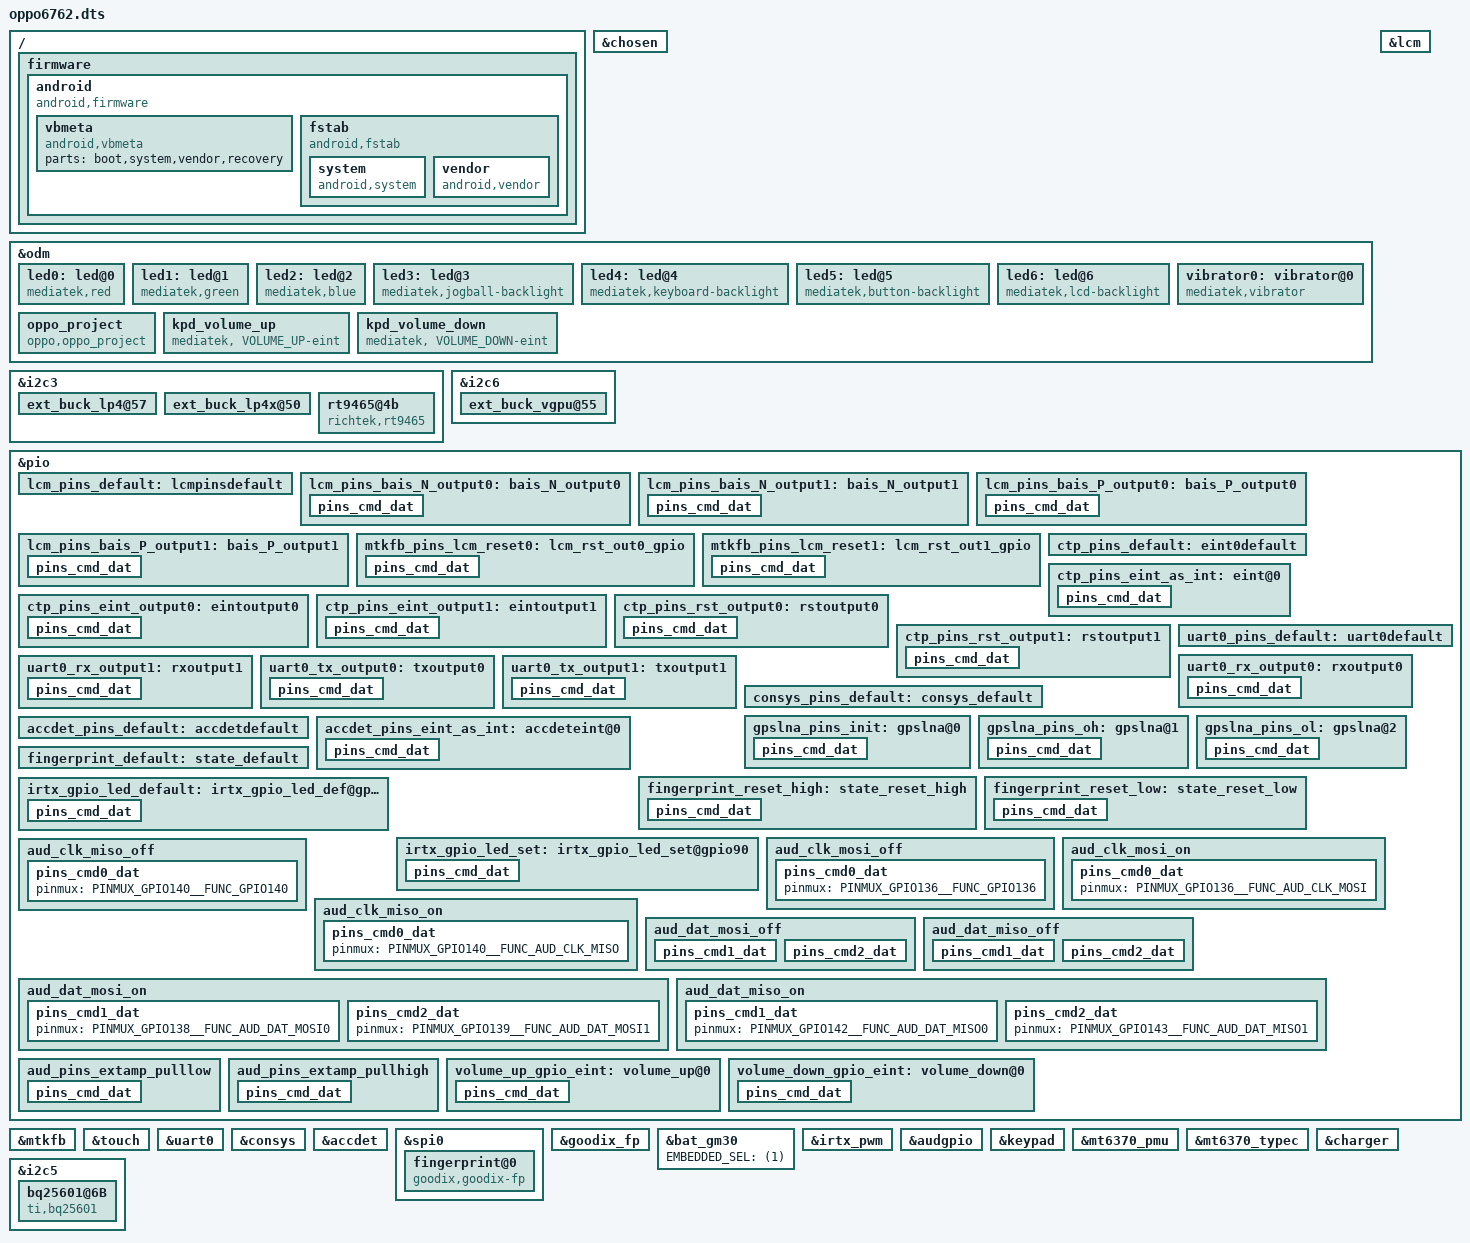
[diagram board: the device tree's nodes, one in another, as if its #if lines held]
/*
 * Copyright (C) 2019 MediaTek Inc.
 *
 * This program is free software; you can redistribute it and/or modify
 * it under the terms of the GNU General Public License version 2 as
 * published by the Free Software Foundation.
 *
 * This program is distributed in the hope that it will be useful,
 * but WITHOUT ANY WARRANTY; without even the implied warranty of
 * MERCHANTABILITY or FITNESS FOR A PARTICULAR PURPOSE.
 * See http://www.gnu.org/licenses/gpl-2.0.html for more details.
 */

#include <dt-bindings/interrupt-controller/arm-gic.h>
#include <dt-bindings/interrupt-controller/irq.h>
#include <dt-bindings/pinctrl/mt6765-pinfunc.h>
#include <dt-bindings/clock/mt6765-clk.h>

/dts-v1/;
/plugin/;

/* chosen */
&chosen {

	/* fpga may has no lk, we need to specify display info here */
	/* fb buffer is reserved using this dts by memory node above */
	atag,videolfb-fb_base_h = <0x0>;
	atag,videolfb-fb_base_l = <0x5e605000>;
	atag,videolfb-islcmfound = <1>;
	/* because no lk, so lcm is not inited */
	atag,videolfb-islcm_inited = <0>;
	atag,videolfb-fps= <6000>;
	atag,videolfb-vramSize= <0x017bb000>;
	atag,videolfb-lcmname= "nt35695B_fhd_dsi_cmd_auo_rt5081_drv";
};

/ {

firmware {
 		android {
 			compatible = "android,firmware";
 #ifdef CONFIG_MTK_AVB20_SUPPORT
 			vbmeta {
 				compatible = "android,vbmeta";
 #ifndef CONFIG_MTK_AB_OTA_UPDATER
 #ifdef CONFIG_MTK_MAIN_VBMETA_IN_BOOT
 				parts = "boot,system,vendor,recovery";
 #else
 				parts = "vbmeta,boot,system,vendor,recovery";
 #endif
 #else
 #ifdef CONFIG_MTK_MAIN_VBMETA_IN_BOOT
 				parts = "boot,system,vendor";
 #else
 				parts = "vbmeta,boot,system,vendor";
 #endif
 #endif
 			};
 #endif
 			fstab {
 				compatible = "android,fstab";
 #if !defined(CONFIG_SYSTEM_AS_ROOT) && !defined(CONFIG_MTK_AB_OTA_UPDATER)
 				system {
 					compatible = "android,system";
 					dev = "/dev/block/platform/bootdevice/by-name/system";
 					type = "ext4";
 //#if defined(VENDOR_EDIT) && defined(CONFIG_EXT4_ASYNC_DISCARD_SUPPORT)
 //yh@PSW.BSP.Storage.EXT4, 2018-11-26 add for ext4 async discard suppot
 					mnt_flags = "ro,discard";
 //#else
 					//*mnt_flags = "ro";
 //#endif
 #ifndef CONFIG_MTK_DM_VERITY_OFF
 #ifdef CONFIG_MTK_AVB20_SUPPORT
 					fsmgr_flags = "wait,avb";
 #else
 					fsmgr_flags = "wait,verify";
 #endif
 #else
 					fsmgr_flags = "wait";
 #endif
 				};
 #endif
 #ifndef CONFIG_MTK_LATE_MOUNT
 				vendor {
 					compatible = "android,vendor";
 					dev = "/dev/block/platform/bootdevice/by-name/vendor";
 					type = "ext4";
 //#if defined(VENDOR_EDIT) && defined(CONFIG_EXT4_ASYNC_DISCARD_SUPPORT)
 //yh@PSW.BSP.Storage.EXT4, 2018-11-26 add for ext4 async discard suppot
 					mnt_flags = "ro,discard";
 //#else
 					//*mnt_flags = "ro";
 //#endif
 #ifndef CONFIG_MTK_AB_OTA_UPDATER
 #ifndef CONFIG_MTK_DM_VERITY_OFF
 #ifdef CONFIG_MTK_AVB20_SUPPORT
 					fsmgr_flags = "wait,avb";
 #else
 					fsmgr_flags = "wait,verify";
 #endif
 #else
 					fsmgr_flags = "wait";
 #endif
 #else
 #ifndef CONFIG_MTK_DM_VERITY_OFF
 #ifdef CONFIG_MTK_AVB20_SUPPORT
 					fsmgr_flags = "wait,slotselect,avb";
 #else
 					fsmgr_flags = "wait,slotselect,verify";
 #endif
 #else
 					fsmgr_flags = "wait,slotselect";
 #endif
 #endif
 				};
 #endif
 #if 0
 #ifdef CONFIG_TARGET_COPY_OUT_ODM
 				odm {
 					compatible = "android,odm";
 					dev = "/dev/block/platform/bootdevice/by-name/odm";
 					type = "ext4";
 					mnt_flags = "ro";
 #ifndef CONFIG_MTK_AB_OTA_UPDATER
 #ifndef CONFIG_MTK_DM_VERITY_OFF
 #ifdef CONFIG_MTK_AVB20_SUPPORT
 					fsmgr_flags = "wait,avb";
 #else
 					fsmgr_flags = "wait,verify";
 #endif
 #else
 					fsmgr_flags = "wait";
 #endif
 #else
 #ifndef CONFIG_MTK_DM_VERITY_OFF
 #ifdef CONFIG_MTK_AVB20_SUPPORT
 					fsmgr_flags = "wait,slotselect,avb";
 #else
 					fsmgr_flags = "wait,slotselect,verify";
 #endif
 #else
 					fsmgr_flags = "wait,slotselect";
 #endif
 #endif
 				};
 #endif
 #endif
 
 			};
 		};
 	};

};

&odm {
	led0:led@0 {
		compatible = "mediatek,red";
		led_mode = <0>;
		data = <1>;
		pwm_config = <0 0 0 0 0>;
	};
	led1:led@1 {
		compatible = "mediatek,green";
		led_mode = <0>;
		data = <1>;
		pwm_config = <0 0 0 0 0>;
	};
	led2:led@2 {
		compatible = "mediatek,blue";
		led_mode = <0>;
		data = <1>;
		pwm_config = <0 0 0 0 0>;
	};
	led3:led@3 {
		compatible = "mediatek,jogball-backlight";
		led_mode = <0>;
		data = <1>;
		pwm_config = <0 0 0 0 0>;
	};
	led4:led@4 {
		compatible = "mediatek,keyboard-backlight";
		led_mode = <0>;
		data = <1>;
		pwm_config = <0 0 0 0 0>;
	};
	led5:led@5 {
		compatible = "mediatek,button-backlight";
		led_mode = <0>;
		data = <1>;
		pwm_config = <0 0 0 0 0>;
	};
	led6:led@6 {
		compatible = "mediatek,lcd-backlight";
/* zhangmengchun@ODM.Muiltimedia.lcm  2018/11/28 modify for bring up lcm */
		led_mode = <4>;
		data = <1>;
		pwm_config = <0 3 0 0 0>;
	};
	vibrator0:vibrator@0 {
		compatible = "mediatek,vibrator";
		vib_timer = <25>;
		vib_limit = <9>;
		vib_vol= <11>;
	};

//#ifdef VENDOR_EDIT
/*Bin.Li@EXP.BSP.bootloader.bootflow, 2017/05/15, Add for oppo project */
	oppo_project:oppo_project {
		compatible = "oppo,oppo_project";
	};
//#endif /*VENDOR_EDIT*/

//#ifdef VENDOR_EDIT
/* Bin.Li@EXP.BSP.bootloader.bootflow, 2017/05/16, Add volume up and down */
       kpd_volume_up:kpd_volume_up {
               compatible = "mediatek, VOLUME_UP-eint";
               interrupt-parent = <&pio>;
               interrupts = <20 IRQ_TYPE_EDGE_FALLING 20 0>;
               debounce = <32000>;
               status = "okay";
       };

       kpd_volume_down:kpd_volume_down {
               compatible = "mediatek, VOLUME_DOWN-eint";
               interrupt-parent = <&pio>;
               interrupts = <94 IRQ_TYPE_EDGE_FALLING 94 0>;
               debounce = <32000>;
               status = "okay";
       };
//#endif
};

&i2c3 {
	ext_buck_lp4@57 {
		regulator-name ="ext_buck_vdd2";
		regulator-min-microvolt = <300000>;
		regulator-max-microvolt = <1300000>;
		vsel_pin = <0>;
	};

	ext_buck_lp4x@50 {
		regulator-name ="ext_buck_vddq";
		regulator-min-microvolt = <300000>;
		regulator-max-microvolt = <1300000>;
		vsel_pin = <1>;
	};
};

&i2c6 {
	ext_buck_vgpu@55 {
		regulator-name ="ext_buck_vgpu";
		regulator-min-microvolt = <300000>;
		regulator-max-microvolt = <1300000>;
		vsel_pin = <2>;
	};
};

/* zhangmengchun@ODM.Muiltimedia.lcm  2018/11/28 modify for bring up lcm */
/* lcm moudle */
&lcm {
	pinctrl-names = "default", "state_bais_N_output0", "state_bais_N_output1",
		"state_bais_P_output0", "state_bais_P_output1";
	pinctrl-0 = <&lcm_pins_default>;
	pinctrl-1 = <&lcm_pins_bais_N_output0>;
	pinctrl-2 = <&lcm_pins_bais_N_output1>;
	pinctrl-3 = <&lcm_pins_bais_P_output0>;
	pinctrl-4 = <&lcm_pins_bais_P_output1>;
	status = "okay";
};
&pio {
	lcm_pins_default: lcmpinsdefault {
	};
	lcm_pins_bais_N_output0: bais_N_output0 {
		pins_cmd_dat {
			pinmux = <PINMUX_GPIO165__FUNC_GPIO165>;
			slew-rate = <1>;
			output-low;
		};
	};
	lcm_pins_bais_N_output1: bais_N_output1 {
		pins_cmd_dat {
			pinmux = <PINMUX_GPIO165__FUNC_GPIO165>;
			slew-rate = <1>;
			output-high;
		};
	};
	lcm_pins_bais_P_output0: bais_P_output0 {
		pins_cmd_dat {
			pinmux = <PINMUX_GPIO166__FUNC_GPIO166>;
			slew-rate = <1>;
			output-low;
		};
	};
	lcm_pins_bais_P_output1: bais_P_output1 {
		pins_cmd_dat {
			pinmux = <PINMUX_GPIO166__FUNC_GPIO166>;
			slew-rate = <1>;
			output-high;
		};
	};
};
/* lcm moudle end */
/* Xianfei.Wang@ODM.Muiltimedia.lcm  2019/1/15 modify for lcm_rst by pinctrl */
/* DISPSYS GPIO standardization start*/
&pio {
        mtkfb_pins_lcm_reset0: lcm_rst_out0_gpio {
                pins_cmd_dat {
                        pinmux = <PINMUX_GPIO45__FUNC_GPIO45>;
                        slew-rate = <1>;
                        output-low;
                };
        };
        mtkfb_pins_lcm_reset1: lcm_rst_out1_gpio {
                pins_cmd_dat {
                        pinmux = <PINMUX_GPIO45__FUNC_GPIO45>;
                        slew-rate = <1>;
                        output-high;
                };
	};
};
&mtkfb {
        pinctrl-names ="lcm_rst_out0_gpio",  "lcm_rst_out1_gpio";
        pinctrl-0 = <&mtkfb_pins_lcm_reset0>;
        pinctrl-1 = <&mtkfb_pins_lcm_reset1>;
        status = "okay";
		oppo_display_cabc_support;
		oppo_display_ffl_support;
};
/* DISPSYS GPIO standardization end*/
/* TOUCH start */
&touch {
	tpd-resolution = <720 1560>;
	use-tpd-button = <0>;
	tpd-key-num = <3>;
	tpd-key-local= <139 172 158 0>;
	tpd-key-dim-local = <90 883 100 40 230
				 883 100 40 370 883 100 40 0 0 0 0>;
	tpd-max-touch-num = <10>;
	tpd-filter-enable = <0>;
	tpd-filter-pixel-density = <146>;
	tpd-filter-custom-prameters = <0 0 0 0 0 0 0 0 0 0 0 0>;
	tpd-filter-custom-speed = <0 0 0>;
	pinctrl-names = "default", "state_eint_as_int", "state_eint_output0",
		"state_eint_output1", "state_rst_output0", "state_rst_output1";
	pinctrl-0 = <&ctp_pins_default>;
	pinctrl-1 = <&ctp_pins_eint_as_int>;
	pinctrl-2 = <&ctp_pins_eint_output0>;
	pinctrl-3 = <&ctp_pins_eint_output1>;
	pinctrl-4 = <&ctp_pins_rst_output0>;
	pinctrl-5 = <&ctp_pins_rst_output1>;
	status = "okay";
};
&pio {
	ctp_pins_default: eint0default {
	};
	ctp_pins_eint_as_int: eint@0 {
		pins_cmd_dat {
			pinmux = <PINMUX_GPIO0__FUNC_GPIO0>;
			slew-rate = <0>;
			bias-disable;
		};
	};
	ctp_pins_eint_output0: eintoutput0 {
		pins_cmd_dat {
			pinmux = <PINMUX_GPIO0__FUNC_GPIO0>;
			slew-rate = <1>;
			output-low;
		};
	};
	ctp_pins_eint_output1: eintoutput1 {
		pins_cmd_dat {
			pinmux = <PINMUX_GPIO0__FUNC_GPIO0>;
			slew-rate = <1>;
			output-high;
		};
	};
	ctp_pins_rst_output0: rstoutput0 {
		pins_cmd_dat {
			pinmux = <PINMUX_GPIO178__FUNC_GPIO178>;
			slew-rate = <1>;
			output-low;
		};
	};
	ctp_pins_rst_output1: rstoutput1 {
		pins_cmd_dat {
			pinmux = <PINMUX_GPIO178__FUNC_GPIO178>;
			slew-rate = <1>;
			output-high;
		};
	};
};
/* TOUCH end */
/*serial start*/
/*Wenchao.Du@BSP.Kernel.Driver 2019/01/17 disable uart for user*/
&uart0 {
	pinctrl-names = "default", "state_uart0_rx_output0", "state_uart0_rx_output1",
		"state_uart0_tx_output0", "state_uart0_tx_output1";
	pinctrl-0 = <&uart0_pins_default>;
	pinctrl-1 = <&uart0_rx_output0>;
	pinctrl-2 = <&uart0_rx_output1>;
	pinctrl-3 = <&uart0_tx_output0>;
	pinctrl-4 = <&uart0_tx_output1>;
	status = "okay";
};
&pio {
	uart0_pins_default: uart0default {
	};
	uart0_rx_output0: rxoutput0 {
		pins_cmd_dat {
			pinmux = <PINMUX_GPIO95__FUNC_GPIO95>;
			slew-rate = <1>;
			output-low;
		};
	};
	uart0_rx_output1: rxoutput1 {
		pins_cmd_dat {
			pinmux = <PINMUX_GPIO95__FUNC_GPIO95>;
			slew-rate = <1>;
			output-high;
		};
	};
	uart0_tx_output0: txoutput0 {
		pins_cmd_dat {
			pinmux = <PINMUX_GPIO96__FUNC_GPIO96>;
			slew-rate = <1>;
			output-low;
		};
	};
	uart0_tx_output1: txoutput1 {
		pins_cmd_dat {
			pinmux = <PINMUX_GPIO96__FUNC_GPIO96>;
			slew-rate = <1>;
			output-high;
		};
	};
};
/*serial end*/
/* CONSYS GPIO standardization */
&pio {
	consys_pins_default: consys_default {
	};
	gpslna_pins_init: gpslna@0 {
		pins_cmd_dat {
			pinmux = <PINMUX_GPIO91__FUNC_GPIO91>;
			slew-rate = <0>;
			bias-disable;
			output-low;
		};
	};
	gpslna_pins_oh: gpslna@1 {
		pins_cmd_dat {
			pinmux = <PINMUX_GPIO91__FUNC_GPIO91>;
			slew-rate = <1>;
			output-high;
		};
	};
	gpslna_pins_ol: gpslna@2 {
		pins_cmd_dat {
			pinmux = <PINMUX_GPIO91__FUNC_GPIO91>;
			slew-rate = <1>;
			output-low;
		};
	};
};
&consys {
	pinctrl-names = "default", "gps_lna_state_init",
		"gps_lna_state_oh", "gps_lna_state_ol";
	pinctrl-0 = <&consys_pins_default>;
	pinctrl-1 = <&gpslna_pins_init>;
	pinctrl-2 = <&gpslna_pins_oh>;
	pinctrl-3 = <&gpslna_pins_ol>;
	status = "okay";
};
/* CONSYS end */

/* accdet start */
&accdet {
	accdet-mic-vol = <6>;
	headset-mode-setting = <0x500 0x500 1 0x1f0 0x800 0x800 0x20 0x44>;
	accdet-plugout-debounce = <1>;
	accdet-mic-mode = <1>;
	headset-eint-level-pol = <8>;
	headset-three-key-threshold = <0 80 220 400>;
	headset-three-key-threshold-CDD = <0 121 192 600>;
	headset-four-key-threshold = <0 58 121 192 400>;
	pinctrl-names = "default", "state_eint_as_int";
	pinctrl-0 = <&accdet_pins_default>;
	pinctrl-1 = <&accdet_pins_eint_as_int>;
	status = "okay";
};
&pio {
	accdet_pins_default: accdetdefault {
	};
	accdet_pins_eint_as_int: accdeteint@0 {
		pins_cmd_dat {
			pinmux = <PINMUX_GPIO9__FUNC_GPIO9>;
			slew-rate = <0>;
			bias-disable;
		};
	};
};
/* accdet end */

/* FINGERPRINT start */
&spi0 {
	#address-cells = <1>;
	#size-cells = <0>;
	fingerprint@0 {
		compatible = "goodix,goodix-fp";
		reg = <0>;
		spi-max-frequency = <8000000>;
		netlink-event = <30>;
		status = "okay";
	};
};

&goodix_fp {
	pinctrl-names = "default", "reset_high", "reset_low";
	pinctrl-0 = <&fingerprint_default>;
	pinctrl-1 = <&fingerprint_reset_high>;
	pinctrl-2 = <&fingerprint_reset_low>;
	status = "okay";
};

&pio {
	fingerprint_default: state_default {
	};
	fingerprint_reset_high: state_reset_high {
		pins_cmd_dat {
			pinmux = <PINMUX_GPIO172__FUNC_GPIO172>;
			slew-rate = <1>;
			output-high;
		};
	};
	fingerprint_reset_low: state_reset_low {
		pins_cmd_dat {
			pinmux = <PINMUX_GPIO172__FUNC_GPIO172>;
			slew-rate = <1>;
			output-low;
		};
	};
};
/* FINGERPRINT end */

/* battery end */
&bat_gm30 {
	EMBEDDED_SEL = <(1)>;
};
/* battery end */

/* IRTX GPIO end */
&irtx_pwm {
	pinctrl-names = "irtx_gpio_led_default", "irtx_gpio_led_set";
	pinctrl-0 = <&irtx_gpio_led_default>;
	pinctrl-1 = <&irtx_gpio_led_set>;
	status = "okay";
};
&pio {
	irtx_gpio_led_default:irtx_gpio_led_def@gpio90 {
		pins_cmd_dat {
			pinmux = <PINMUX_GPIO90__FUNC_GPIO90>;
			slew-rate = <1>;
			bias-disable;
			output-low;
			input-schmitt-enable = <0>;
		};
	};

	irtx_gpio_led_set:irtx_gpio_led_set@gpio90 {
		pins_cmd_dat {
			pinmux = <PINMUX_GPIO90__FUNC_PWM0>;
			slew-rate = <1>;
			output-high;
		};
	};
};
/* IRTX GPIO Settings -End */

/* AUDIO GPIO standardization */
&audgpio {
	pinctrl-names = "aud_clk_mosi_off",
			"aud_clk_mosi_on",
			"aud_clk_miso_off",
			"aud_clk_miso_on",
			"aud_dat_mosi_off",
			"aud_dat_mosi_on",
			"aud_dat_miso_off",
			"aud_dat_miso_on",
/* zhangmengchun@ODM.Muiltimedia.audio  2018/11/28 modify for bring up audio */
			"extamp-pulllow",
			"extamp-pullhigh";
	pinctrl-0 = <&aud_clk_mosi_off>;
	pinctrl-1 = <&aud_clk_mosi_on>;
	pinctrl-2 = <&aud_clk_miso_off>;
	pinctrl-3 = <&aud_clk_miso_on>;
	pinctrl-4 = <&aud_dat_mosi_off>;
	pinctrl-5 = <&aud_dat_mosi_on>;
	pinctrl-6 = <&aud_dat_miso_off>;
	pinctrl-7 = <&aud_dat_miso_on>;
/* zhangmengchun@ODM.Muiltimedia.audio  2018/11/28 modify for bring up audio */
	pinctrl-8 = <&aud_pins_extamp_pulllow>;
	pinctrl-9 = <&aud_pins_extamp_pullhigh>;
	status = "okay";
};

&pio {
	aud_clk_mosi_off: aud_clk_mosi_off {
		pins_cmd0_dat {
			pinmux = <PINMUX_GPIO136__FUNC_GPIO136>;
		};
	};

	aud_clk_mosi_on: aud_clk_mosi_on {
		pins_cmd0_dat {
			pinmux = <PINMUX_GPIO136__FUNC_AUD_CLK_MOSI>;
		};
	};

	aud_clk_miso_off: aud_clk_miso_off {
		pins_cmd0_dat {
			pinmux = <PINMUX_GPIO140__FUNC_GPIO140>;
		};
	};

	aud_clk_miso_on: aud_clk_miso_on {
		pins_cmd0_dat {
			pinmux = <PINMUX_GPIO140__FUNC_AUD_CLK_MISO>;
		};
	};

	aud_dat_mosi_off: aud_dat_mosi_off {
		pins_cmd1_dat {
			pinmux = <PINMUX_GPIO138__FUNC_GPIO138>;
			input-enable;
			slew-rate = <0>;
			bias-disable;
		};
		pins_cmd2_dat {
			pinmux = <PINMUX_GPIO139__FUNC_GPIO139>;
			input-enable;
			slew-rate = <0>;
			bias-disable;
		};
	};

	aud_dat_mosi_on: aud_dat_mosi_on {
		pins_cmd1_dat {
			pinmux = <PINMUX_GPIO138__FUNC_AUD_DAT_MOSI0>;
		};
		pins_cmd2_dat {
			pinmux = <PINMUX_GPIO139__FUNC_AUD_DAT_MOSI1>;
		};
	};

	aud_dat_miso_off: aud_dat_miso_off {
		pins_cmd1_dat {
			pinmux = <PINMUX_GPIO142__FUNC_GPIO142>;
			input-enable;
			slew-rate = <0>;
			bias-disable;
		};
		pins_cmd2_dat {
			pinmux = <PINMUX_GPIO143__FUNC_GPIO143>;
			input-enable;
			slew-rate = <0>;
			bias-disable;
		};
	};

	aud_dat_miso_on: aud_dat_miso_on {
		pins_cmd1_dat {
			pinmux = <PINMUX_GPIO142__FUNC_AUD_DAT_MISO0>;
		};
		pins_cmd2_dat {
			pinmux = <PINMUX_GPIO143__FUNC_AUD_DAT_MISO1>;
		};
	};

/* zhangmengchun@ODM.Muiltimedia.audio  2018/11/28 modify for bring up audio */
	aud_pins_extamp_pulllow: aud_pins_extamp_pulllow {
		pins_cmd_dat {
			pinmux = <PINMUX_GPIO150__FUNC_GPIO150>;
			slew-rate = <1>;
			output-low;
		};
	};

	aud_pins_extamp_pullhigh: aud_pins_extamp_pullhigh {
		pins_cmd_dat {
			pinmux = <PINMUX_GPIO150__FUNC_GPIO150>;
			slew-rate = <1>;
			output-high;
		};
	};

};
/* AUDIO end */

//#ifdef VENDOR_EDIT
/* Bin.Li@EXP.BSP.bootloader.bootflow, 2017/05/16, Add volume up and down */
&keypad {
	keypad,volume-up	= <&pio 20 0x00>;
	keypad,volume-down	= <&pio 94 0x00>;
	pinctrl-names = "volume_up_as_int", "volume_down_as_int";
	pinctrl-0 = <&volume_up_gpio_eint>;
	pinctrl-1 = <&volume_down_gpio_eint>;
	status = "okay";
};

&pio {
	volume_up_gpio_eint:volume_up@0{
		pins_cmd_dat {
			pinmux = <PINMUX_GPIO20__FUNC_GPIO20>;
			slew-rate = <0>;  /*direction 0:in, 1:out*/
			bias-pull-up = <00>;
			input-enable;
		};
	};
	volume_down_gpio_eint:volume_down@0{
		pins_cmd_dat {
			pinmux = <PINMUX_GPIO94__FUNC_GPIO94>;
			slew-rate = <0>;  /*direction 0:in, 1:out*/
			bias-pull-up = <00>;
			input-enable;
		};
	};
};
//#endif /*VENDOR_EDIT*/


&mt6370_pmu {
	mt6370,intr_gpio_num = <11>; /* direct defined GPIO num */
	mt6370,intr_gpio = <&pio 11 0x0>;
};

&mt6370_typec {
	mt6370pd,intr_gpio_num = <41>; /* direct defined GPIO num */
	mt6370pd,intr_gpio = <&pio 41 0x0>;
};

&charger {
	algorithm_name = "SwitchCharging";
	chg1_ta_ac_charger_current = <2000000>;
	chg2_ta_ac_charger_current = <2000000>;
};

&i2c5 {
	bq25601@6B {
			compatible = "ti,bq25601";
			reg = <0x6b>;
			ti,bq2560x,usb-vlim = <4600>;
			ti,bq2560x,usb-ilim = <500>;
			ti,bq2560x,usb-vreg = <4400>;
			ti,bq2560x,usb-ichg = <500>;

			ti,bq2560x,precharge-current = <256>;
			ti,bq2560x,termination-current = <300>;
			ti,bq2560x,boost-voltage = <4998>;
			ti,bq2560x,boost-current = <1200>;
			ti,bq2560x,enable_term;
			ti,bq2560x,stat-pin-ctrl = <3>;
			ti,bq2560x,vac-ovp-threshold = <6500>;

	};
};

&i2c3 {
	rt9465@4b {
		compatible = "richtek,rt9465";
		reg = <0x4b>;
		status = "okay";
		rt,en_gpio_num = <176>;
		rt,en_gpio = <&pio 176 0x0>;
		rt,intr_gpio_num = <23>; /* direct defined GPIO num */
		rt,intr_gpio = <&pio 23 0x0>;
		interrupt-names = "wdtmri";
		charger_name = "secondary_chg";
		ichg = <1500000>; /* uA */
		mivr = <4500000>; /* uV */
		cv = <4550000>; /* uV */
		ieoc = <700000>; /* uA */
		safety_timer = <12>; /* hour */
		en_st; /* safety timer */
		/* en_te; */
		en_wdt;
	};
};



#include <oppo6762/cust.dtsi>
#include "cust_mt6765_camera.dtsi"
/*End of this file, DO NOT ADD ANYTHING HERE*/
